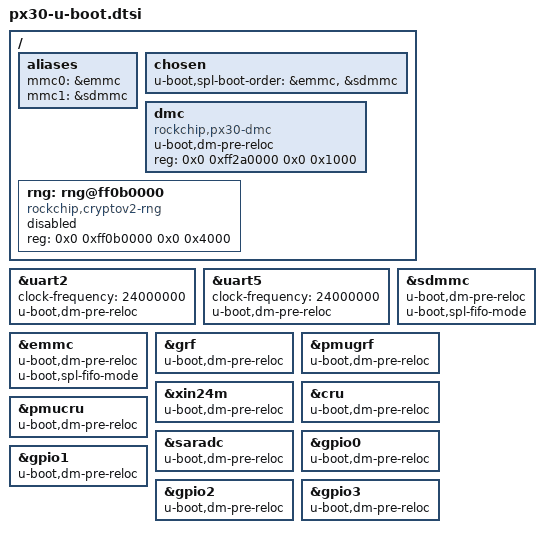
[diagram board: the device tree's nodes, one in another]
// SPDX-License-Identifier: (GPL-2.0+ OR MIT)
/*
 * (C) Copyright 2019 Rockchip Electronics Co., Ltd
 */

#include "rockchip-u-boot.dtsi"

/ {
	aliases {
		mmc0 = &emmc;
		mmc1 = &sdmmc;
	};

	chosen {
		u-boot,spl-boot-order = &emmc, &sdmmc;
	};

	dmc {
		u-boot,dm-pre-reloc;
		compatible = "rockchip,px30-dmc", "syscon";
		reg = <0x0 0xff2a0000 0x0 0x1000>;
	};

	rng: rng@ff0b0000 {
		compatible = "rockchip,cryptov2-rng";
		reg = <0x0 0xff0b0000 0x0 0x4000>;
		status = "disabled";
	};
};

&uart2 {
	clock-frequency = <24000000>;
	u-boot,dm-pre-reloc;
};

&uart5 {
	clock-frequency = <24000000>;
	u-boot,dm-pre-reloc;
};

&sdmmc {
	u-boot,dm-pre-reloc;

	/* mmc to sram can't do dma, prevent aborts transferring TF-A parts */
	u-boot,spl-fifo-mode;
};

&emmc {
	u-boot,dm-pre-reloc;

	/* mmc to sram can't do dma, prevent aborts transferring TF-A parts */
	u-boot,spl-fifo-mode;
};

&grf {
	u-boot,dm-pre-reloc;
};

&pmugrf {
	u-boot,dm-pre-reloc;
};

&xin24m {
	u-boot,dm-pre-reloc;
};

&cru {
	u-boot,dm-pre-reloc;
	/delete-property/ assigned-clocks;
	/delete-property/ assigned-clock-rates;
};

&pmucru {
	u-boot,dm-pre-reloc;
	/delete-property/ assigned-clocks;
	/delete-property/ assigned-clock-rates;
};

&saradc {
	u-boot,dm-pre-reloc;
	status = "okay";
};

&gpio0 {
	u-boot,dm-pre-reloc;
};

&gpio1 {
	u-boot,dm-pre-reloc;
};

&gpio2 {
	u-boot,dm-pre-reloc;
};

&gpio3 {
	u-boot,dm-pre-reloc;
};
